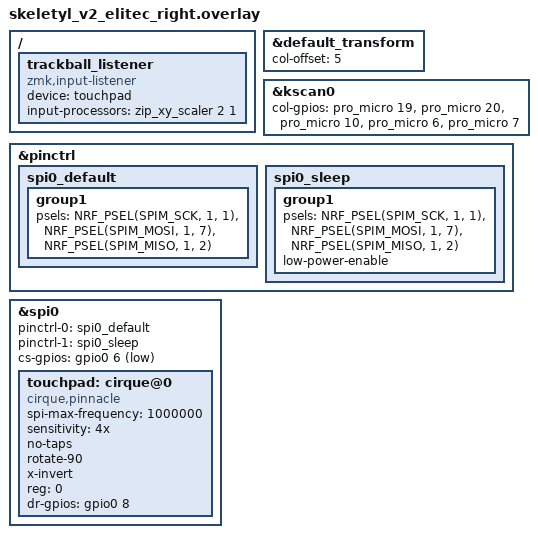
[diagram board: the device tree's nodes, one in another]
/*
 * Copyright (c) 2020 ZMK Contributors
 *
 * SPDX-License-Identifier: MIT
 */
 
#include "skeletyl_v2_elitec.dtsi"
#include <dt-bindings/zmk/input_transform.h>
#include <zephyr/dt-bindings/input/input-event-codes.h>

&default_transform {
	col-offset = <5>;
};

&kscan0 {
	col-gpios
		= <&pro_micro 19 (GPIO_ACTIVE_HIGH)>,
		  <&pro_micro 20 (GPIO_ACTIVE_HIGH)>,
		  <&pro_micro 10 (GPIO_ACTIVE_HIGH)>,
		  <&pro_micro  6 (GPIO_ACTIVE_HIGH)>,
		  <&pro_micro  7 (GPIO_ACTIVE_HIGH)>
		;
};

&pinctrl {
    spi0_default: spi0_default {
        group1 {
            psels = <NRF_PSEL(SPIM_SCK,  1, 1)>,
                    <NRF_PSEL(SPIM_MOSI, 1, 7)>,
                    <NRF_PSEL(SPIM_MISO, 1, 2)>;

        };
    };

    spi0_sleep: spi0_sleep {
        group1 {
            psels = <NRF_PSEL(SPIM_SCK,  1, 1)>,
                    <NRF_PSEL(SPIM_MOSI, 1, 7)>,
                    <NRF_PSEL(SPIM_MISO, 1, 2)>;
            low-power-enable;
        };
    };
};

&spi0 {
    pinctrl-0 = <&spi0_default>;
    pinctrl-1 = <&spi0_sleep>;
    pinctrl-names = "default", "sleep";
    cs-gpios = <&gpio0 6 GPIO_ACTIVE_LOW>;

    touchpad: cirque@0 {
        compatible = "cirque,pinnacle";
        spi-max-frequency = <1000000>; //1MHZ
        sensitivity = "4x";
        no-taps;
        rotate-90;
        x-invert;
        status = "okay";
        reg = <0>;
        dr-gpios = <&gpio0 8 (GPIO_ACTIVE_HIGH)>;
    };
    status = "okay";
};

/ {
    trackball_listener {
        compatible = "zmk,input-listener";
        device = <&touchpad>;
        input-processors = <&zip_xy_scaler 2 1>;
    };
};
